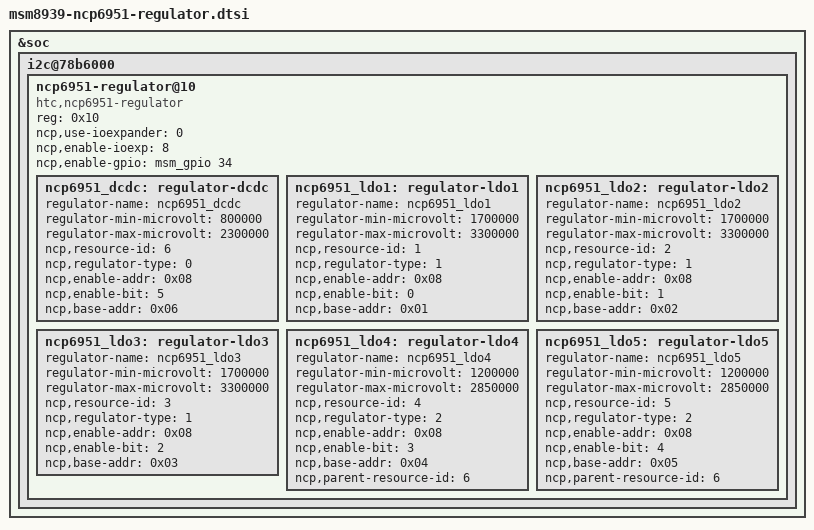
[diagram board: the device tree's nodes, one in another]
/* Copyright (c) 2014, The Linux Foundation. All rights reserved.
 *
 * This program is free software; you can redistribute it and/or modify
 * it under the terms of the GNU General Public License version 2 and
 * only version 2 as published by the Free Software Foundation.
 *
 * This program is distributed in the hope that it will be useful,
 * but WITHOUT ANY WARRANTY; without even the implied warranty of
 * MERCHANTABILITY or FITNESS FOR A PARTICULAR PURPOSE.  See the
 * GNU General Public License for more details.
 */

&soc {
	i2c@78b6000 { /* BLSP1 QUP4 */
		ncp6951-regulator@10 {
			compatible = "htc,ncp6951-regulator";
			reg = <0x10>;
			ncp,use-ioexpander = <0>; /* 1: en_pin at gpio-expander */
			ncp,enable-ioexp = <8>;
			ncp,enable-gpio = <&msm_gpio 34 0>;

			ncp6951_dcdc: regulator-dcdc {
				regulator-name = "ncp6951_dcdc";
				regulator-min-microvolt = <800000>;
				regulator-max-microvolt = <2300000>;
				ncp,resource-id = <6>;
				ncp,regulator-type = <0>;
				ncp,enable-addr = <0x08>;
				ncp,enable-bit = <5>;
				ncp,base-addr = <0x06>;
				//ncp,init-microvolt = <1900000>;
			};

			ncp6951_ldo1: regulator-ldo1 {
				regulator-name = "ncp6951_ldo1";
				regulator-min-microvolt = <1700000>;
				regulator-max-microvolt = <3300000>;
				ncp,resource-id = <1>;
				ncp,regulator-type = <1>;
				ncp,enable-addr = <0x08>;
				ncp,enable-bit = <0>;
				ncp,base-addr = <0x01>;
			};

			ncp6951_ldo2: regulator-ldo2 {
				regulator-name = "ncp6951_ldo2";
				regulator-min-microvolt = <1700000>;
				regulator-max-microvolt = <3300000>;
				ncp,resource-id = <2>;
				ncp,regulator-type = <1>;
				ncp,enable-addr = <0x08>;
				ncp,enable-bit = <1>;
				ncp,base-addr = <0x02>;
			};

			ncp6951_ldo3: regulator-ldo3 {
				regulator-name = "ncp6951_ldo3";
				regulator-min-microvolt = <1700000>;
				regulator-max-microvolt = <3300000>;
				ncp,resource-id = <3>;
				ncp,regulator-type = <1>;
				ncp,enable-addr = <0x08>;
				ncp,enable-bit = <2>;
				ncp,base-addr = <0x03>;
			};

			ncp6951_ldo4: regulator-ldo4 {
				regulator-name = "ncp6951_ldo4";
				regulator-min-microvolt = <1200000>;
				regulator-max-microvolt = <2850000>;
				ncp,resource-id = <4>;
				ncp,regulator-type = <2>;
				ncp,enable-addr = <0x08>;
				ncp,enable-bit = <3>;
				ncp,base-addr = <0x04>;
				ncp,parent-resource-id = <6>;
			};

			ncp6951_ldo5: regulator-ldo5 {
				regulator-name = "ncp6951_ldo5";
				regulator-min-microvolt = <1200000>;
				regulator-max-microvolt = <2850000>;
				ncp,resource-id = <5>;
				ncp,regulator-type = <2>;
				ncp,enable-addr = <0x08>;
				ncp,enable-bit = <4>;
				ncp,base-addr = <0x05>;
				ncp,parent-resource-id = <6>;
			};
		};
	};
};
